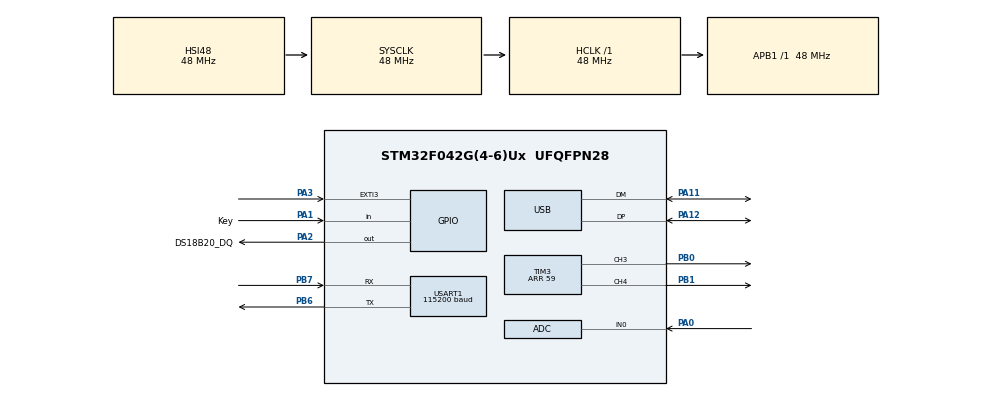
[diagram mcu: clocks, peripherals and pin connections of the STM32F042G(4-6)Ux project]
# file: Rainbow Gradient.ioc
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ADC.Overrun=ADC_OVR_DATA_OVERWRITTEN
ADC.SamplingTime=ADC_SAMPLETIME_55CYCLES_5
Dma.Request0=TIM3_CH3
Dma.Request1=TIM3_CH4/UP
Dma.TIM3_CH3.0.Direction=DMA_MEMORY_TO_PERIPH
Dma.TIM3_CH3.0.Instance=DMA1_Channel2
Dma.TIM3_CH3.0.MemDataAlignment=DMA_MDATAALIGN_HALFWORD
Dma.TIM3_CH3.0.MemInc=DMA_MINC_ENABLE
Dma.TIM3_CH3.0.Mode=DMA_NORMAL
Dma.TIM3_CH3.0.PeriphDataAlignment=DMA_PDATAALIGN_HALFWORD
Dma.TIM3_CH3.0.PeriphInc=DMA_PINC_DISABLE
Dma.TIM3_CH3.0.Priority=DMA_PRIORITY_HIGH
Dma.TIM3_CH4/UP.1.Direction=DMA_MEMORY_TO_PERIPH
Dma.TIM3_CH4/UP.1.Instance=DMA1_Channel3
Dma.TIM3_CH4/UP.1.MemDataAlignment=DMA_MDATAALIGN_HALFWORD
Dma.TIM3_CH4/UP.1.MemInc=DMA_MINC_ENABLE
Dma.TIM3_CH4/UP.1.Mode=DMA_NORMAL
Dma.TIM3_CH4/UP.1.PeriphDataAlignment=DMA_PDATAALIGN_HALFWORD
Dma.TIM3_CH4/UP.1.PeriphInc=DMA_PINC_DISABLE
Dma.TIM3_CH4/UP.1.Priority=DMA_PRIORITY_HIGH
Mcu.Family=STM32F0
Mcu.Name=STM32F042G(4-6)Ux
Mcu.Package=UFQFPN28
NVIC.DMA1_Channel2_3_IRQn=true\:0\:0\:false\:false\:true\:false\:true\:true
NVIC.EXTI2_3_IRQn=true\:0\:0\:false\:false\:true\:true\:true\:true
PA0.Mode=IN0
PA0.Signal=ADC_IN0
PA1.GPIO_Label=Key
PA1.Signal=GPIO_Input
PA11.Mode=Device
PA11.Signal=USB_DM
PA12.Mode=Device
PA12.Signal=USB_DP
PA13.Mode=Serial_Wire
PA13.Signal=SYS_SWDIO
PA14.Mode=Serial_Wire
PA14.Signal=SYS_SWCLK
PA2.GPIO_Label=DS18B20_DQ
PA2.GPIO_ModeDefaultOutputPP=GPIO_MODE_OUTPUT_OD
PA2.GPIO_PuPd=GPIO_NOPULL
PA2.PinState=GPIO_PIN_SET
PA2.Signal=GPIO_Output
PA3.GPIO_ModeDefaultEXTI=GPIO_MODE_IT_RISING_FALLING
PA3.Signal=GPXTI3
PB0.Signal=S_TIM3_CH3
PB1.Signal=S_TIM3_CH4
PB6.Mode=Asynchronous
PB6.Signal=USART1_TX
PB7.Mode=Asynchronous
PB7.Signal=USART1_RX
ProjectManager.HeapSize=0x200
ProjectManager.StackSize=0x400
ProjectManager.TargetToolchain=MDK-ARM V5.32
RCC.AHBFreq_Value=48000000
RCC.APB1Freq_Value=48000000
RCC.APB1TimFreq_Value=48000000
RCC.HCLKFreq_Value=48000000
RCC.SYSCLKFreq_VALUE=48000000
RCC.SYSCLKSource=RCC_SYSCLKSOURCE_HSI48
SH.S_TIM3_CH3.0=TIM3_CH3,PWM Generation3 CH3
SH.S_TIM3_CH4.0=TIM3_CH4,PWM Generation4 CH4
TIM1.ClockDivision=TIM_CLOCKDIVISION_DIV2
TIM1.Period=59
TIM14.Prescaler=47
TIM3.Channel-PWM\ Generation3\ CH3=TIM_CHANNEL_3
TIM3.Channel-PWM\ Generation4\ CH4=TIM_CHANNEL_4
TIM3.Period=59
USART1.BaudRate=115200
USART1.VirtualMode-Asynchronous=VM_ASYNC
VP_SYS_VS_PINREMAP.Mode=PINREMAP
VP_TIM14_VS_ClockSourceINT.Mode=Enable_Timer
VP_TIM1_VS_ClockSourceINT.Mode=Internal
VP_TIM3_VS_ClockSourceINT.Mode=Internal
board=custom

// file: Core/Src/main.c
/* USER CODE BEGIN Header */
/**
  ******************************************************************************
  * @file           : main.c
  * @brief          : Main program body
  ******************************************************************************
  * @attention
  *
  * Copyright (c) 2026 STMicroelectronics.
  * All rights reserved.
  *
  * This software is licensed under terms that can be found in the LICENSE file
  * in the root directory of this software component.
  * If no LICENSE file comes with this software, it is provided AS-IS.
  *
  ******************************************************************************
  */
/* USER CODE END Header */
#include "main.h"
#include "adc.h"
#include "dma.h"
#include "tim.h"
#include "usart.h"
#include "usb.h"
#include "gpio.h"

/* USER CODE BEGIN Includes */
#include "led.h"
/* USER CODE END Includes */

void SystemClock_Config(void);

int main(void)
{

  /* MCU Configuration--------------------------------------------------------*/

  /* Reset of all peripherals, Initializes the Flash interface and the Systick. */
  HAL_Init();

  /* Configure the system clock */
  SystemClock_Config();

  /* Initialize all configured peripherals */
  MX_GPIO_Init();
  MX_DMA_Init();
  MX_TIM1_Init();
  MX_USART1_UART_Init();
  MX_USB_PCD_Init();
  MX_TIM3_Init();
  MX_TIM14_Init();
  MX_ADC_Init();
  /* USER CODE BEGIN 2 */
  LED_Init();
/* USER CODE END 2 */

  /* Infinite loop */
  while (1)
  {

    /* USER CODE BEGIN 3 */
    LED_RainbowTask();
  }
  /* USER CODE END 3 */
}

void SystemClock_Config(void)
{
  RCC_OscInitTypeDef RCC_OscInitStruct = {0};
  RCC_ClkInitTypeDef RCC_ClkInitStruct = {0};
  RCC_PeriphCLKInitTypeDef PeriphClkInit = {0};

  /** Initializes the RCC Oscillators according to the specified parameters
  * in the RCC_OscInitTypeDef structure.
  */
  RCC_OscInitStruct.OscillatorType = RCC_OSCILLATORTYPE_HSI14|RCC_OSCILLATORTYPE_HSI48;
  RCC_OscInitStruct.HSI48State = RCC_HSI48_ON;
  RCC_OscInitStruct.HSI14State = RCC_HSI14_ON;
  RCC_OscInitStruct.HSI14CalibrationValue = 16;
  RCC_OscInitStruct.PLL.PLLState = RCC_PLL_NONE;
  if (HAL_RCC_OscConfig(&RCC_OscInitStruct) != HAL_OK)
  {
    Error_Handler();
  }

  /** Initializes the CPU, AHB and APB buses clocks
  */
  RCC_ClkInitStruct.ClockType = RCC_CLOCKTYPE_HCLK|RCC_CLOCKTYPE_SYSCLK
                              |RCC_CLOCKTYPE_PCLK1;
  RCC_ClkInitStruct.SYSCLKSource = RCC_SYSCLKSOURCE_HSI48;
  RCC_ClkInitStruct.AHBCLKDivider = RCC_SYSCLK_DIV1;
  RCC_ClkInitStruct.APB1CLKDivider = RCC_HCLK_DIV1;

  if (HAL_RCC_ClockConfig(&RCC_ClkInitStruct, FLASH_LATENCY_1) != HAL_OK)
  {
    Error_Handler();
  }
  PeriphClkInit.PeriphClockSelection = RCC_PERIPHCLK_USB|RCC_PERIPHCLK_USART1;
  PeriphClkInit.Usart1ClockSelection = RCC_USART1CLKSOURCE_PCLK1;
  PeriphClkInit.UsbClockSelection = RCC_USBCLKSOURCE_HSI48;

  if (HAL_RCCEx_PeriphCLKConfig(&PeriphClkInit) != HAL_OK)
  {
    Error_Handler();
  }
}

void Error_Handler(void)
{
  __disable_irq();
  while (1)
  {
  }
}
